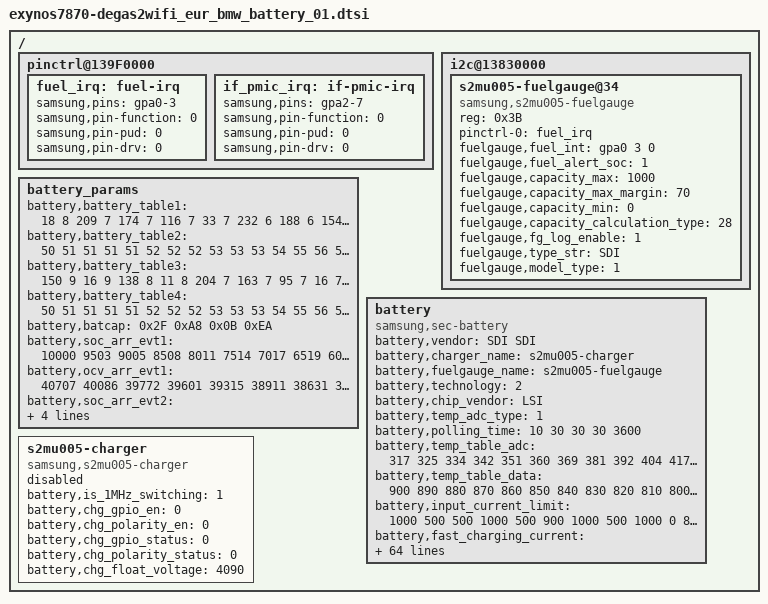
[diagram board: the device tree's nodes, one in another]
/*
 * SAMSUNG UNIVERSAL5433 board device tree source
 *
 * Copyright (c) 2015 Samsung Electronics Co., Ltd.
 *		http://www.samsung.com
 *
 * This program is free software; you can redistribute it and/or modify
 * it under the terms of the GNU General Public License version 2 as
 * published by the Free Software Foundation.
*/

/ {
	pinctrl@139F0000 {
		fuel_irq: fuel-irq {
			samsung,pins = "gpa0-3";
			samsung,pin-function = <0>;
			samsung,pin-pud = <0>;
			samsung,pin-drv = <0>;
		};
	};

	pinctrl@139F0000 {
		if_pmic_irq: if-pmic-irq {
			samsung,pins = "gpa2-7";
			samsung,pin-function = <0>;
			samsung,pin-pud = <0>;
			samsung,pin-drv = <0>;
		};
	};

	i2c@13830000 {
		status = "okay";
		s2mu005-fuelgauge@34 {
			compatible = "samsung,s2mu005-fuelgauge";
			reg = <0x3B>;
			pinctrl-names = "default";
			pinctrl-0 = <&fuel_irq>;
			fuelgauge,fuel_int = <&gpa0 3 0>;
			fuelgauge,fuel_alert_soc = <1>;
			fuelgauge,capacity_max = <1000>;
			fuelgauge,capacity_max_margin = <70>;
			fuelgauge,capacity_min = <0>;
			fuelgauge,capacity_calculation_type = <28>;
			fuelgauge,fg_log_enable = <1>;
			fuelgauge,type_str = "SDI";
			fuelgauge,model_type = <1>;
		};
	};

	battery_params {
			battery,battery_table1 = <18 8 209 7 174 7 116 7 33 7 232 6 188 6 154 6 125 6 100 6 78 6 59 6 38 6 19 6 250 5 208 5 156 5 138 5 93 5 109 3 108
			                                      3 109 1 0 8 154 7 52 7 206 6 105 6 3 6 157 5 55 5 209 4 107 4 6 4 160 3 58 3 212 2 111 2 9 2 163 1 61 1 215 0 113 0 12 0 235 15>;

			battery,battery_table2 = <50 51 51 51 51 52 52 52 53 53 53 54 55 56 56 57 57 58 58 59 61 154>;
			
			battery,battery_table3 = <150 9 16 9 138 8 11 8 204 7 163 7 95 7 16 7 216 6 175 6 141 6 113 6 88 6 67 6 46 6 25 6 1 6 216 5 163 5 140 5 95 5 108 3 213 8
			                                      104 8 251 7 142 7 33 7 180 6 71 6 218 5 109 5 0 5 147 4 38 4 185 3 76 3 223 2 114 2 5 2 152 1 43 1 190 0 81 0 228 15>;
			battery,battery_table4 = <50 51 51 51 51 52 52 52 53 53 53 54 55 56 56 57 57 58 58 59 61 154>;

			battery,batcap = <0x2F 0xA8 0x0B 0xEA>; /* [0x0F] [0x0E] [0x11] [0x10] */
			
			battery,soc_arr_evt1 = <10000 9503 9005 8508 8011 7514 7017 6519 6022 5525 5028 4531 4034 3537 3040 2542 2046 1549 1052 554 57 (-100)>;
			battery,ocv_arr_evt1 = <40707 40086 39772 39601 39315 38911 38631 38420 38252 38110 37989 37882 37788 37688 37593 37473 37265 37010 36923 36705 34276 31700>;
			
			battery,soc_arr_evt2 = <11039 10507 9975 9443 8911 8378 7846 7314 6782 6250 5718 5185 4653 4121 3589 3057 2525 1993 1460 928 396 (-136)>;
			battery,ocv_arr_evt2 = <41982 41329 40676 40055 39747 39544 39215 38827 38557 38353 38188 38050 37930 37826 37723 37622 37503 37307 37048 36932 36716 34276>;

			battery,FG_Accumulative_rate_evt2 = <0x99 0x07>;
	};

	battery {
		status = "okay";

		pinctrl-names = "default";

		compatible = "samsung,sec-battery";
		battery,vendor = "SDI SDI";
		battery,charger_name = "s2mu005-charger";
		battery,fuelgauge_name = "s2mu005-fuelgauge";
		battery,technology = <2>; /* POWER_SUPPLY_TECHNOLOGY_LION */

		battery,chip_vendor = "LSI";
		battery,temp_adc_type = <1>; /* SEC_BATTERY_ADC_TYPE_AP */

		battery,polling_time = <10 30 30 30 3600>;

		battery,temp_table_adc = <317 325 334 342 351 360 369 381 392 404 417 432 447 462 477 493 508
					523 538 553 568 589 610 630 651 672 694 716 737 759 781 805 828 852 875
					872 905 938 971 1004 1037 1070 1103 1136 1169 1202 1242 1283 1323 1364 1404
					1446 1489 1531 1574 1616 1654 1692 1731 1769 1807 1850 1893 1936 1979 2023 2067
					2112 2156 2200 2246 2291 2337 2382 2428 2471 2514 2558 2601 2644 2687 2729 2771
					2813 2855 2897 2934 2972 3009 3047 3084 3106 3129 3151 3174 3196 3241 3287 3332
					3378 3423 3440 3458 3475 3493 3510 3528 3546 3565 3583 3601>;

		battery,temp_table_data = <900 890 880 870 860 850 840 830 820 810 800 790 780 770 760 750 740 730 720 710 700 690
					   680 670 660 650 640 630 620 610 600 590 580 570 560 550 540 530 520 510 500 490 480 470
					   460 450 440 430 420 410 400 390 380 370 360 350 340 330 320 310 300 290 280 270 260 250
					   240 230 220 210 200 190 180 170 160 150 140 130 120 110 100 90 80 70 60 50 40 30 20 10
					   0 (-10) (-20) (-30) (-40) (-50) (-60) (-70) (-80) (-90) (-100) (-110) (-120) (-130) (-140)
					   (-150) (-160) (-170) (-180) (-190) (-200)>;

		battery,input_current_limit = <1000 500 500 1000 500 900 1000 500 1000 0 820 820 820 1000 1000 0 0 400 700 1000 300 1000 1000 0 1000 1000 1000 1000 80 1000 1000 1000 1000 1000 820 820>;
		battery,fast_charging_current = <1000 0 0 1000 500 1000 1000 500 1000 0 1000 1000 1000 1000 1000 0 0 400 700 1000 300 1000 1000 0 1000 1000 1000 1000 80 1000 1000 1000 0 1000 1000 1000>;
		battery,full_check_current_1st = <200 0 0 200 200 200 200 200 200 0 200 200 200 200 200 0 0 200 200 200 200 200 200 0 200 200 200 200 0 200 200 200 0 200 200 200>;
		battery,full_check_current_2nd = <150 0 0 150 150 150 150 150 150 0 150 150 150 150 150 0 0 150 150 150 150 150 150 0 150 150 150 150 0 150 150 150 0 150 150 150>;

		battery,wireless_cc_cv = <86>;
		battery,inbat_voltage = <1>;
		battery,inbat_voltage_table_adc = <2980 2941 2890 2877 2850 2807 2780 2736 2702 2660 2628 2602 2575 2545 2518>;
		battery,inbat_voltage_table_data = <410 405 400 395 390 385 380 375 370 365 360 355 350 345 340>;

		battery,adc_check_count = <5>;

		battery,cable_check_type = <4>; /* SEC_BATTERY_CABLE_CHECK_PSY */
		battery,cable_source_type = <1>; /* SEC_BATTERY_CABLE_SOURCE_EXTERNAL */
		battery,polling_type = <1>; /* SEC_BATTERY_MONITOR_ALARM */
		battery,monitor_initial_count = <0>;

		battery,battery_check_type = <0>; /* SEC_BATTERY_CHECK_NONE */
		battery,check_count = <0>;

		battery,check_adc_max = <1440>;
		battery,check_adc_min = <0>;

		battery,ovp_uvlo_check_type = <3>; /* SEC_BATTERY_OVP_UVLO_CHGPOLLING */

		battery,thermal_source = <2>; /* SEC_BATTERY_THERMAL_SOURCE_ADC */

		battery,temp_check_type = <2>; /* SEC_BATTERY_TEMP_CHECK_TEMP */
		battery,temp_check_count = <1>;
		battery,temp_highlimit_threshold_normal = <800>;
		battery,temp_highlimit_recovery_normal = <750>;
		battery,temp_high_threshold_normal = <500>;
		battery,temp_high_recovery_normal = <465>;
		battery,temp_low_threshold_normal = <0>;
		battery,temp_low_recovery_normal = <55>;
		battery,temp_highlimit_threshold_lpm = <800>;
		battery,temp_highlimit_recovery_lpm = <750>;
		battery,temp_high_threshold_lpm = <500>;
		battery,temp_high_recovery_lpm = <465>;
		battery,temp_low_threshold_lpm = <0>;
		battery,temp_low_recovery_lpm = <55>;
		battery,full_check_type = <2>; /* SEC_BATTERY_FULLCHARGED_FG_CURRENT */
		battery,full_check_type_2nd = <0>; /* NONE */
		battery,full_check_count = <1>;
		battery,chg_gpio_full_check = <0>;
		battery,chg_polarity_full_check = <1>;

		battery,chg_high_temp_1st = <530>;
		battery,chg_high_temp_2nd = <530>;
		battery,chg_high_temp_recovery = <525>;
		battery,chg_charging_limit_current = <1300>;
		battery,chg_charging_limit_current_2nd = <1300>;
		battery,chg_skip_check_capacity = <10>;
		battery,chg_skip_check_time = <600>;

		battery,wpc_high_temp = <420>;
		battery,wpc_high_temp_recovery = <410>;
		battery,wpc_charging_limit_current = <450>;

		/* SEC_BATTERY_FULL_CONDITION_SOC |
		   SEC_BATTERY_FULL_CONDITION_NOTIMEFULL |
		   SEC_BATTERY_FULL_CONDITION_VCELL */
		battery,full_condition_type = <15>;
		battery,full_condition_soc = <93>;
		battery,full_condition_vcell = <4000>;

		battery,recharge_check_count = <2>;
		battery,recharge_condition_type = <4>; /* SEC_BATTERY_RECHARGE_CONDITION_VCELL */
		battery,recharge_condition_soc = <98>;
		battery,recharge_condition_vcell = <4040>;

		battery,charging_total_time = <21600>;
		battery,recharging_total_time = <5400>;
		battery,charging_reset_time = <0>;


		io-channels = <&exynos_adc 1>, <&exynos_adc 5>;
		io-channel-names = "adc-temp", "adc-in-bat";
		#io-channel-cells = <1>;
		io-channel-ranges;

		battery,chg_float_voltage = <4090>;

		
	};

	s2mu005-charger {
		status = "disable";
		compatible = "samsung,s2mu005-charger";
		battery,is_1MHz_switching = <1>;
		battery,chg_gpio_en = <0>;
		battery,chg_polarity_en = <0>;
		battery,chg_gpio_status = <0>;
		battery,chg_polarity_status = <0>;
		battery,chg_float_voltage = <4090>;
	};
};
